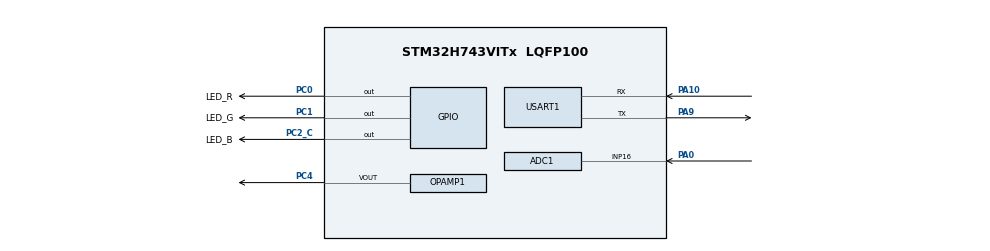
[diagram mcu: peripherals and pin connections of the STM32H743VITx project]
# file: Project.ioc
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ADC1.Channel-0\#ChannelRegularConversion=ADC_CHANNEL_16
ADC1.ClockPrescaler=ADC_CLOCK_ASYNC_DIV2
ADC1.ConversionDataManagement=ADC_CONVERSIONDATA_DMA_CIRCULAR
ADC1.ExternalTrigConv=ADC_EXTERNALTRIG_T1_TRGO
ADC1.NbrOfConversionFlag=1
ADC1.OffsetNumber-0\#ChannelRegularConversion=ADC_OFFSET_NONE
ADC1.OffsetSignedSaturation-0\#ChannelRegularConversion=DISABLE
ADC1.Overrun=ADC_OVR_DATA_OVERWRITTEN
ADC1.Rank-0\#ChannelRegularConversion=1
ADC1.Resolution=ADC_RESOLUTION_12B_OPT
ADC1.SamplingTime-0\#ChannelRegularConversion=ADC_SAMPLETIME_1CYCLE_5
ADC1.master=1
CORTEX_M7.AccessPermission_S-Cortex_Memory_Protection_Unit_Region1_Settings_S=MPU_REGION_FULL_ACCESS
CORTEX_M7.AccessPermission_S-Cortex_Memory_Protection_Unit_Region2_Settings_S=MPU_REGION_FULL_ACCESS
CORTEX_M7.AccessPermission_S-Cortex_Memory_Protection_Unit_Region3_Settings_S=MPU_REGION_FULL_ACCESS
CORTEX_M7.AccessPermission_S-Cortex_Memory_Protection_Unit_Region4_Settings_S=MPU_REGION_FULL_ACCESS
CORTEX_M7.AccessPermission_S-Cortex_Memory_Protection_Unit_Region5_Settings_S=MPU_REGION_FULL_ACCESS
CORTEX_M7.AccessPermission_Spec=MPU_REGION_FULL_ACCESS
CORTEX_M7.BaseAddress_S-Cortex_Memory_Protection_Unit_Region1_Settings_S=0x60000000
CORTEX_M7.BaseAddress_S-Cortex_Memory_Protection_Unit_Region2_Settings_S=0x30000000
CORTEX_M7.BaseAddress_S-Cortex_Memory_Protection_Unit_Region3_Settings_S=0x30020000
CORTEX_M7.BaseAddress_S-Cortex_Memory_Protection_Unit_Region4_Settings_S=0x30040000
CORTEX_M7.BaseAddress_S-Cortex_Memory_Protection_Unit_Region5_Settings_S=0x38000000
CORTEX_M7.BaseAddress_Spec=0x24000000
CORTEX_M7.CPU_DCache=Enabled
CORTEX_M7.CPU_ICache=Enabled
CORTEX_M7.DisableExec_Spec=MPU_INSTRUCTION_ACCESS_ENABLE
CORTEX_M7.Enable_S-Cortex_Memory_Protection_Unit_Region1_Settings_S=MPU_REGION_ENABLE
CORTEX_M7.Enable_S-Cortex_Memory_Protection_Unit_Region2_Settings_S=MPU_REGION_ENABLE
CORTEX_M7.Enable_S-Cortex_Memory_Protection_Unit_Region3_Settings_S=MPU_REGION_ENABLE
CORTEX_M7.Enable_S-Cortex_Memory_Protection_Unit_Region4_Settings_S=MPU_REGION_ENABLE
CORTEX_M7.Enable_S-Cortex_Memory_Protection_Unit_Region5_Settings_S=MPU_REGION_ENABLE
CORTEX_M7.IsBufferable_S-Cortex_Memory_Protection_Unit_Region1_Settings_S=MPU_ACCESS_BUFFERABLE
CORTEX_M7.IsBufferable_Spec=MPU_ACCESS_BUFFERABLE
CORTEX_M7.IsCacheable_S-Cortex_Memory_Protection_Unit_Region2_Settings_S=MPU_ACCESS_CACHEABLE
CORTEX_M7.IsCacheable_S-Cortex_Memory_Protection_Unit_Region3_Settings_S=MPU_ACCESS_CACHEABLE
CORTEX_M7.IsCacheable_S-Cortex_Memory_Protection_Unit_Region4_Settings_S=MPU_ACCESS_CACHEABLE
CORTEX_M7.IsCacheable_S-Cortex_Memory_Protection_Unit_Region5_Settings_S=MPU_ACCESS_CACHEABLE
CORTEX_M7.IsCacheable_Spec=MPU_ACCESS_CACHEABLE
CORTEX_M7.IsShareable_Spec=MPU_ACCESS_NOT_SHAREABLE
CORTEX_M7.MPU_Control=MPU_HFNMI_PRIVDEF
CORTEX_M7.Size_S-Cortex_Memory_Protection_Unit_Region1_Settings_S=MPU_REGION_SIZE_64KB
CORTEX_M7.Size_S-Cortex_Memory_Protection_Unit_Region2_Settings_S=MPU_REGION_SIZE_128KB
CORTEX_M7.Size_S-Cortex_Memory_Protection_Unit_Region3_Settings_S=MPU_REGION_SIZE_128KB
CORTEX_M7.Size_S-Cortex_Memory_Protection_Unit_Region4_Settings_S=MPU_REGION_SIZE_32KB
CORTEX_M7.Size_S-Cortex_Memory_Protection_Unit_Region5_Settings_S=MPU_REGION_SIZE_64KB
CORTEX_M7.Size_Spec=MPU_REGION_SIZE_512KB
CORTEX_M7.SubRegionDisable_Spec=0x0
CORTEX_M7.TypeExtField_Spec=MPU_TEX_LEVEL1
CORTEX_M7.default_mode_Activation=1
DAC1.DAC_Channel-DAC_OUT1_Int=DAC_CHANNEL_1
DAC1.DAC_SampleAndHold-DAC_OUT1_Int=DAC_SAMPLEANDHOLD_DISABLE
DAC1.DAC_Trigger-DAC_OUT1_Int=DAC_TRIGGER_T8_TRGO
Dma.ADC1.0.Direction=DMA_PERIPH_TO_MEMORY
Dma.ADC1.0.EventEnable=DISABLE
Dma.ADC1.0.FIFOMode=DMA_FIFOMODE_ENABLE
Dma.ADC1.0.FIFOThreshold=DMA_FIFO_THRESHOLD_FULL
Dma.ADC1.0.Instance=DMA2_Stream0
Dma.ADC1.0.MemBurst=DMA_MBURST_SINGLE
Dma.ADC1.0.MemDataAlignment=DMA_MDATAALIGN_HALFWORD
Dma.ADC1.0.MemInc=DMA_MINC_ENABLE
Dma.ADC1.0.Mode=DMA_CIRCULAR
Dma.ADC1.0.PeriphBurst=DMA_PBURST_SINGLE
Dma.ADC1.0.PeriphDataAlignment=DMA_PDATAALIGN_HALFWORD
Dma.ADC1.0.PeriphInc=DMA_PINC_DISABLE
Dma.ADC1.0.Polarity=HAL_DMAMUX_REQ_GEN_RISING
Dma.ADC1.0.Priority=DMA_PRIORITY_HIGH
Dma.ADC1.0.RequestNumber=1
Dma.ADC1.0.SignalID=NONE
Dma.ADC1.0.SyncEnable=DISABLE
Dma.ADC1.0.SyncPolarity=HAL_DMAMUX_SYNC_NO_EVENT
Dma.ADC1.0.SyncRequestNumber=1
Dma.ADC1.0.SyncSignalID=NONE
Dma.DAC1_CH1.1.Direction=DMA_MEMORY_TO_PERIPH
Dma.DAC1_CH1.1.EventEnable=DISABLE
Dma.DAC1_CH1.1.FIFOMode=DMA_FIFOMODE_DISABLE
Dma.DAC1_CH1.1.Instance=DMA1_Stream0
Dma.DAC1_CH1.1.MemDataAlignment=DMA_MDATAALIGN_HALFWORD
Dma.DAC1_CH1.1.MemInc=DMA_MINC_ENABLE
Dma.DAC1_CH1.1.Mode=DMA_CIRCULAR
Dma.DAC1_CH1.1.PeriphDataAlignment=DMA_PDATAALIGN_HALFWORD
Dma.DAC1_CH1.1.PeriphInc=DMA_PINC_DISABLE
Dma.DAC1_CH1.1.Polarity=HAL_DMAMUX_REQ_GEN_RISING
Dma.DAC1_CH1.1.Priority=DMA_PRIORITY_VERY_HIGH
Dma.DAC1_CH1.1.RequestNumber=1
Dma.DAC1_CH1.1.SignalID=NONE
Dma.DAC1_CH1.1.SyncEnable=DISABLE
Dma.DAC1_CH1.1.SyncPolarity=HAL_DMAMUX_SYNC_NO_EVENT
Dma.DAC1_CH1.1.SyncRequestNumber=1
Dma.DAC1_CH1.1.SyncSignalID=NONE
Dma.Request0=ADC1
Dma.Request1=DAC1_CH1
Mcu.Family=STM32H7
Mcu.Name=STM32H743VITx
Mcu.Package=LQFP100
NVIC.DMA1_Stream0_IRQn=true\:0\:0\:false\:false\:true\:false\:true\:true
NVIC.DMA2_Stream0_IRQn=true\:0\:0\:false\:false\:true\:false\:true\:true
NVIC.PriorityGroup=NVIC_PRIORITYGROUP_4
OPAMP1.PowerMode=OPAMP_POWERMODE_HIGHSPEED
OPAMP1.UserTrimming=OPAMP_TRIMMING_USER
PA0.Mode=IN16-Single-Ended
PA0.Signal=ADC1_INP16
PA10.Mode=Asynchronous
PA10.Signal=USART1_RX
PA13\ (JTMS/SWDIO).Mode=Serial_Wire
PA13\ (JTMS/SWDIO).Signal=DEBUG_JTMS-SWDIO
PA14\ (JTCK/SWCLK).Mode=Serial_Wire
PA14\ (JTCK/SWCLK).Signal=DEBUG_JTCK-SWCLK
PA9.Mode=Asynchronous
PA9.Signal=USART1_TX
PC0.GPIO_Label=LED_R
PC0.PinState=GPIO_PIN_SET
PC0.Signal=GPIO_Output
PC1.GPIO_Label=LED_G
PC1.PinState=GPIO_PIN_SET
PC1.Signal=GPIO_Output
PC2_C.GPIO_Label=LED_B
PC2_C.PinState=GPIO_PIN_SET
PC2_C.Signal=GPIO_Output
PC4.Mode=Follower-DAC_OUT1-INP
PC4.Signal=OPAMP1_VOUT
PH0-OSC_IN\ (PH0).Mode=HSE-External-Oscillator
PH0-OSC_IN\ (PH0).Signal=RCC_OSC_IN
PH1-OSC_OUT\ (PH1).Mode=HSE-External-Oscillator
PH1-OSC_OUT\ (PH1).Signal=RCC_OSC_OUT
ProjectManager.HeapSize=0x2000
ProjectManager.StackSize=0x1000
ProjectManager.TargetToolchain=STM32CubeIDE
RCC.ADCFreq_Value=72000000
RCC.APB1Freq_Value=120000000
RCC.APB2Freq_Value=120000000
RCC.APB3Freq_Value=120000000
RCC.APB4Freq_Value=120000000
RCC.CortexFreq_Value=480000000
RCC.D1PPRE=RCC_APB3_DIV2
RCC.D2PPRE1=RCC_APB1_DIV2
RCC.D2PPRE2=RCC_APB2_DIV2
RCC.D3PPRE=RCC_APB4_DIV2
RCC.DIVM1=5
RCC.DIVM2=25
RCC.DIVN1=192
RCC.DIVN2=504
RCC.DIVP2=7
RCC.HCLKFreq_Value=240000000
RCC.HPRE=RCC_HCLK_DIV2
RCC.PLLSourceVirtual=RCC_PLLSOURCE_HSE
RCC.SYSCLKFreq_VALUE=480000000
RCC.SYSCLKSource=RCC_SYSCLKSOURCE_PLLCLK
RCC.USBFreq_Value=480000000
TIM1.TIM_MasterOutputTrigger=TIM_TRGO_UPDATE
TIM8.TIM_MasterOutputTrigger=TIM_TRGO_UPDATE
USART1.VirtualMode-Asynchronous=VM_ASYNC
VP_DAC1_VS_DACI1.Mode=DAC_OUT1_Int
VP_MEMORYMAP_VS_MEMORYMAP.Mode=CurAppReg
VP_TIM1_VS_ClockSourceINT.Mode=Internal
VP_TIM8_VS_ClockSourceINT.Mode=Internal
board=custom

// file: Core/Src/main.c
/* USER CODE BEGIN Header */
/**
  ******************************************************************************
  * @file           : main.c
  * @brief          : Main program body
  ******************************************************************************
  * @attention
  *
  * Copyright (c) 2025 STMicroelectronics.
  * All rights reserved.
  *
  * This software is licensed under terms that can be found in the LICENSE file
  * in the root directory of this software component.
  * If no LICENSE file comes with this software, it is provided AS-IS.
  *
  ******************************************************************************
  */
/* USER CODE END Header */
#include "main.h"
#include "adc.h"
#include "dac.h"
#include "dma.h"
#include "memorymap.h"
#include "opamp.h"
#include "tim.h"
#include "usart.h"
#include "gpio.h"

/* USER CODE BEGIN Includes */
#include "common_inc.h"
/* USER CODE END Includes */

void SystemClock_Config(void);
static void MPU_Config(void);

int main(void)
{

  /* MPU Configuration--------------------------------------------------------*/
  MPU_Config();

  /* Enable the CPU Cache */

  /* Enable I-Cache---------------------------------------------------------*/
  SCB_EnableICache();

  /* Enable D-Cache---------------------------------------------------------*/
  SCB_EnableDCache();

  /* MCU Configuration--------------------------------------------------------*/

  /* Reset of all peripherals, Initializes the Flash interface and the Systick. */
  HAL_Init();

  /* Configure the system clock */
  SystemClock_Config();

  /* Initialize all configured peripherals */
  MX_GPIO_Init();
  MX_DMA_Init();
  MX_USART1_UART_Init();
  MX_ADC1_Init();
  MX_TIM1_Init();
  MX_DAC1_Init();
  MX_OPAMP1_Init();
  MX_TIM8_Init();

  /* Infinite loop */
  /* USER CODE BEGIN WHILE */
  Main();
  while (1)
  {
    /* USER CODE END WHILE */

  }
}

void SystemClock_Config(void)
{
  RCC_OscInitTypeDef RCC_OscInitStruct = {0};
  RCC_ClkInitTypeDef RCC_ClkInitStruct = {0};

  /** Supply configuration update enable
  */
  HAL_PWREx_ConfigSupply(PWR_LDO_SUPPLY);

  /** Configure the main internal regulator output voltage
  */
  __HAL_PWR_VOLTAGESCALING_CONFIG(PWR_REGULATOR_VOLTAGE_SCALE0);

  while(!__HAL_PWR_GET_FLAG(PWR_FLAG_VOSRDY)) {}

  /** Initializes the RCC Oscillators according to the specified parameters
  * in the RCC_OscInitTypeDef structure.
  */
  RCC_OscInitStruct.OscillatorType = RCC_OSCILLATORTYPE_HSE;
  RCC_OscInitStruct.HSEState = RCC_HSE_ON;
  RCC_OscInitStruct.PLL.PLLState = RCC_PLL_ON;
  RCC_OscInitStruct.PLL.PLLSource = RCC_PLLSOURCE_HSE;
  RCC_OscInitStruct.PLL.PLLM = 5;
  RCC_OscInitStruct.PLL.PLLN = 192;
  RCC_OscInitStruct.PLL.PLLP = 2;
  RCC_OscInitStruct.PLL.PLLQ = 2;
  RCC_OscInitStruct.PLL.PLLR = 2;
  RCC_OscInitStruct.PLL.PLLRGE = RCC_PLL1VCIRANGE_2;
  RCC_OscInitStruct.PLL.PLLVCOSEL = RCC_PLL1VCOWIDE;
  RCC_OscInitStruct.PLL.PLLFRACN = 0;
  if (HAL_RCC_OscConfig(&RCC_OscInitStruct) != HAL_OK)
  {
    Error_Handler();
  }

  /** Initializes the CPU, AHB and APB buses clocks
  */
  RCC_ClkInitStruct.ClockType = RCC_CLOCKTYPE_HCLK|RCC_CLOCKTYPE_SYSCLK
                              |RCC_CLOCKTYPE_PCLK1|RCC_CLOCKTYPE_PCLK2
                              |RCC_CLOCKTYPE_D3PCLK1|RCC_CLOCKTYPE_D1PCLK1;
  RCC_ClkInitStruct.SYSCLKSource = RCC_SYSCLKSOURCE_PLLCLK;
  RCC_ClkInitStruct.SYSCLKDivider = RCC_SYSCLK_DIV1;
  RCC_ClkInitStruct.AHBCLKDivider = RCC_HCLK_DIV2;
  RCC_ClkInitStruct.APB3CLKDivider = RCC_APB3_DIV2;
  RCC_ClkInitStruct.APB1CLKDivider = RCC_APB1_DIV2;
  RCC_ClkInitStruct.APB2CLKDivider = RCC_APB2_DIV2;
  RCC_ClkInitStruct.APB4CLKDivider = RCC_APB4_DIV2;

  if (HAL_RCC_ClockConfig(&RCC_ClkInitStruct, FLASH_LATENCY_4) != HAL_OK)
  {
    Error_Handler();
  }
}

 /* MPU Configuration */

void MPU_Config(void)
{
  MPU_Region_InitTypeDef MPU_InitStruct = {0};

  /* Disables the MPU */
  HAL_MPU_Disable();

  /** Initializes and configures the Region and the memory to be protected
  */
  MPU_InitStruct.Enable = MPU_REGION_ENABLE;
  MPU_InitStruct.Number = MPU_REGION_NUMBER0;
  MPU_InitStruct.BaseAddress = 0x24000000;
  MPU_InitStruct.Size = MPU_REGION_SIZE_512KB;
  MPU_InitStruct.SubRegionDisable = 0x0;
  MPU_InitStruct.TypeExtField = MPU_TEX_LEVEL1;
  MPU_InitStruct.AccessPermission = MPU_REGION_FULL_ACCESS;
  MPU_InitStruct.DisableExec = MPU_INSTRUCTION_ACCESS_ENABLE;
  MPU_InitStruct.IsShareable = MPU_ACCESS_NOT_SHAREABLE;
  MPU_InitStruct.IsCacheable = MPU_ACCESS_CACHEABLE;
  MPU_InitStruct.IsBufferable = MPU_ACCESS_BUFFERABLE;

  HAL_MPU_ConfigRegion(&MPU_InitStruct);

  /** Initializes and configures the Region and the memory to be protected
  */
  MPU_InitStruct.Number = MPU_REGION_NUMBER1;
  MPU_InitStruct.BaseAddress = 0x60000000;
  MPU_InitStruct.Size = MPU_REGION_SIZE_64KB;
  MPU_InitStruct.TypeExtField = MPU_TEX_LEVEL0;
  MPU_InitStruct.IsCacheable = MPU_ACCESS_NOT_CACHEABLE;

  HAL_MPU_ConfigRegion(&MPU_InitStruct);

  /** Initializes and configures the Region and the memory to be protected
  */
  MPU_InitStruct.Number = MPU_REGION_NUMBER2;
  MPU_InitStruct.BaseAddress = 0x30000000;
  MPU_InitStruct.Size = MPU_REGION_SIZE_128KB;
  MPU_InitStruct.IsCacheable = MPU_ACCESS_CACHEABLE;
  MPU_InitStruct.IsBufferable = MPU_ACCESS_NOT_BUFFERABLE;

  HAL_MPU_ConfigRegion(&MPU_InitStruct);

  /** Initializes and configures the Region and the memory to be protected
  */
  MPU_InitStruct.Number = MPU_REGION_NUMBER3;
  MPU_InitStruct.BaseAddress = 0x30020000;

  HAL_MPU_ConfigRegion(&MPU_InitStruct);

  /** Initializes and configures the Region and the memory to be protected
  */
  MPU_InitStruct.Number = MPU_REGION_NUMBER4;
  MPU_InitStruct.BaseAddress = 0x30040000;
  MPU_InitStruct.Size = MPU_REGION_SIZE_32KB;

  HAL_MPU_ConfigRegion(&MPU_InitStruct);

  /** Initializes and configures the Region and the memory to be protected
  */
  MPU_InitStruct.Number = MPU_REGION_NUMBER5;
  MPU_InitStruct.BaseAddress = 0x38000000;
  MPU_InitStruct.Size = MPU_REGION_SIZE_64KB;

  HAL_MPU_ConfigRegion(&MPU_InitStruct);
  /* Enables the MPU */
  HAL_MPU_Enable(MPU_HFNMI_PRIVDEF);

}

void Error_Handler(void)
{
  __disable_irq();
  while (1)
  {
  }
}
